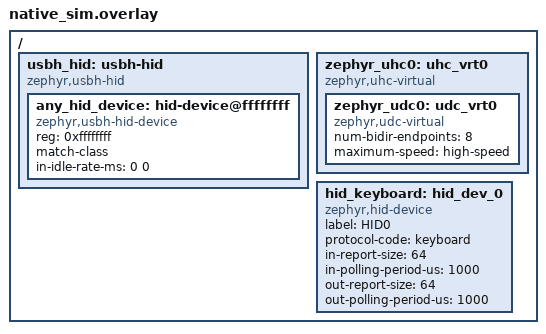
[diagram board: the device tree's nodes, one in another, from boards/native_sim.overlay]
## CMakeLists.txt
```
# SPDX-FileCopyrightText: Copyright 2026 Renesas, Embedd
# SPDX-License-Identifier: Apache-2.0

cmake_minimum_required(VERSION 3.20.0)

find_package(Zephyr REQUIRED HINTS $ENV{ZEPHYR_BASE})
project(test_usbh_hid)

include(${ZEPHYR_BASE}/samples/subsys/usb/common/common.cmake)

target_include_directories(app PRIVATE ${ZEPHYR_BASE}/tests/subsys/usb/host/common)
target_include_directories(app PRIVATE ${ZEPHYR_BASE}/subsys/usb/host)

target_sources(app PRIVATE src/keyboard.c src/hid_keyboard.c)
```

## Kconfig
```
# SPDX-FileCopyrightText: Copyright 2026 Renesas, Embedd
# SPDX-License-Identifier: Apache-2.0

config SYS_CLOCK_TICKS_PER_SEC
	default 1000000 if BOARD_NATIVE_SIM

# Source common USB sample options used to initialize new experimental USB
# device stack. The scope of these options is limited to USB samples in project
# tree, you cannot use them in your own application.
source "samples/subsys/usb/common/Kconfig.sample_usbd"

source "Kconfig.zephyr"
```

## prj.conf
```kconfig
# SPDX-FileCopyrightText: Copyright 2026 Renesas, Embedd
# SPDX-License-Identifier: Apache-2.0

CONFIG_LOG=y
CONFIG_ZTEST=y

CONFIG_USB_DEVICE_STACK_NEXT=y
CONFIG_SAMPLE_USBD_PID=0xFFFF
CONFIG_SAMPLE_USBD_REMOTE_WAKEUP=y
CONFIG_SAMPLE_USBD_PRODUCT="Zephyr USB HID Test"

CONFIG_UHC_DRIVER=y
CONFIG_USB_HOST_STACK=y

CONFIG_USBH_HID_CLASS=y
CONFIG_USBH_HID_ROUTE_TO_INPUT=y

CONFIG_INPUT=y
CONFIG_INPUT_MODE_SYNCHRONOUS=y
```

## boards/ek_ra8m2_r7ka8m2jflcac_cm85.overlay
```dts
/*
 * Copyright (c) 2026 Renesas Electronics Corporation
 *
 * SPDX-License-Identifier: Apache-2.0
 */

/ {
	usbh_hid: usbh-hid {
		compatible = "zephyr,usbh-hid";
		#address-cells = <1>;
		#size-cells = <0>;

		any_hid_device: hid-device@ffffffff {
			compatible = "zephyr,usbh-hid-device";
			reg = <0xffffffff>;
			match-class;
			in-idle-rate-ms = <0 0>;
		};
	};

	hid_keyboard: hid_dev_0 {
		compatible = "zephyr,hid-device";
		label = "HID0";
		protocol-code = "keyboard";
		in-report-size = <64>;
		in-polling-period-us = <1000>;
		out-report-size = <64>;
		out-polling-period-us = <1000>;
	};
};
```

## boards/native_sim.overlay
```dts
/*
 * SPDX-FileCopyrightText: Copyright 2026 Renesas, Embedd
 * SPDX-License-Identifier: Apache-2.0
 */

/delete-node/ &zephyr_udc0;

/ {
	usbh_hid: usbh-hid {
		compatible = "zephyr,usbh-hid";

		#address-cells = <1>;
		#size-cells = <0>;

		any_hid_device: hid-device@ffffffff {
		compatible = "zephyr,usbh-hid-device";
		reg = <0xffffffff>;
		match-class;
		in-idle-rate-ms = <0 0>;
		status="okay";
		};
	};
};

/ {
	zephyr_uhc0: uhc_vrt0 {
		compatible = "zephyr,uhc-virtual";

		zephyr_udc0: udc_vrt0 {
			compatible = "zephyr,udc-virtual";
			num-bidir-endpoints = <8>;
			maximum-speed = "high-speed";
		};
	};

	hid_keyboard: hid_dev_0 {
		compatible = "zephyr,hid-device";
		label = "HID0";
		protocol-code = "keyboard";
		in-report-size = <64>;
		in-polling-period-us = <1000>;
		out-report-size = <64>;
		out-polling-period-us = <1000>;
	};
};
```

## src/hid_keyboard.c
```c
/*
 * SPDX-FileCopyrightText: Copyright 2026 Renesas, Embedd
 * SPDX-License-Identifier: Apache-2.0
 */

#include <zephyr/ztest.h>
#include <zephyr/kernel.h>
#include <zephyr/device.h>
#include <zephyr/drivers/gpio.h>
#include <zephyr/input/input.h>
#include <zephyr/usb/usbd.h>
#include <zephyr/usb/class/usbd_hid.h>

#include "hid_keyboard.h"

static const uint8_t hid_report_desc[] = HID_KEYBOARD_REPORT_DESC();

static uint32_t kb_duration;
static uint8_t report_value;

static void kb_iface_ready(const struct device *dev, const bool ready)
{
}

static int kb_get_report(const struct device *dev, const uint8_t type, const uint8_t id,
			 const uint16_t len, uint8_t *const buf)
{
	return 0;
}

static int kb_set_report(const struct device *dev, const uint8_t type, const uint8_t id,
			 const uint16_t len, const uint8_t *const buf)
{
	if (type != HID_REPORT_TYPE_OUTPUT) {
		return -ENOTSUP;
	}

	return 0;
}

/* Idle duration is stored but not used to calculate idle reports. */
static void kb_set_idle(const struct device *dev, const uint8_t id, const uint32_t duration)
{
	kb_duration = duration;
}

static uint32_t kb_get_idle(const struct device *dev, const uint8_t id)
{
	return kb_duration;
}

static void kb_set_protocol(const struct device *dev, const uint8_t proto)
{
}

static void kb_output_report(const struct device *dev, const uint16_t len, const uint8_t *const buf)
{
	zassert_equal(1, len, "Wrong report length");
	kb_set_report(dev, HID_REPORT_TYPE_OUTPUT, 0u, len, buf);
	report_value = buf[0];
}

static struct hid_device_ops kb_ops = {
	.iface_ready = kb_iface_ready,
	.get_report = kb_get_report,
	.set_report = kb_set_report,
	.set_idle = kb_set_idle,
	.get_idle = kb_get_idle,
	.set_protocol = kb_set_protocol,
	.output_report = kb_output_report,
};

int hid_keyboard_register(void)
{
	const struct device *hid_dev = DEVICE_DT_GET(DT_NODELABEL(hid_keyboard));
	int result = 0;

	if (!device_is_ready(hid_dev)) {
		return -EIO;
	}

	result = hid_device_register(hid_dev, hid_report_desc, sizeof(hid_report_desc), &kb_ops);
	if (result != 0) {
		return result;
	}

	return 0;
}

uint8_t hid_keyboard_get_report_value(void)
{
	return report_value;
}
```

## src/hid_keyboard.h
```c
/*
 * SPDX-FileCopyrightText: Copyright 2026 Renesas, Embedd
 * SPDX-License-Identifier: Apache-2.0
 */

#ifndef HID_KEYBOARD_H_INCLUDED
#define HID_KEYBOARD_H_INCLUDED

#include <stdbool.h>
#include <stdint.h>

int hid_keyboard_register(void);
uint8_t hid_keyboard_get_report_value(void);

/**
 * @brief Configure the result the emulated keyboard's Get Report handler should give
 *
 * @param error 0 for a successful (dummy) report, a negative errno value to make the
 *              device reject (stall) the next Get Report requests
 */
void hid_keyboard_set_get_report_error(int error);

/**
 * @brief Configure whether the emulated keyboard advertises Set Idle support
 *
 * @param supported false to make the device reject (stall) Set Idle requests
 */
void hid_keyboard_set_idle_supported(bool supported);

#endif /* HID_KEYBOARD_H_INCLUDED */
```

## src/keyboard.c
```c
/*
 * SPDX-FileCopyrightText: Copyright 2026 Renesas, Embedd
 * SPDX-License-Identifier: Apache-2.0
 */

#include <zephyr/ztest.h>
#include <zephyr/usb/usbd.h>
#include <zephyr/usb/class/hid.h>
#include <zephyr/logging/log.h>
#include <zephyr/input/input.h>
#include <sample_usbd.h>
#include <zephyr/usb/class/usbd_hid.h>
#include <zephyr/usb/class/usbh_hid.h>

#include "usbh_desc.h"
#include "usbh_device.h"
#include "hid_keyboard.h"

LOG_MODULE_REGISTER(usbh_test_hid, LOG_LEVEL_INF);

#define MAX_EVENTS 16

struct usbh_hid_keyboard_suite_fixture {
	size_t expected_event_index;
	struct input_event expected_events[MAX_EVENTS];
	struct k_sem sync;
};

static struct device const *hid_dev = DEVICE_DT_GET(DT_NODELABEL(hid_keyboard));
static struct device const *usbh_hid_dev = DEVICE_DT_GET(DT_NODELABEL(any_hid_device));
static struct usbd_context *test_usbd;

USBH_CONTROLLER_DEFINE(test_uhs_ctx, DEVICE_DT_GET(DT_NODELABEL(zephyr_uhc0)));

struct usbh_context *const uhs_ctx = &test_uhs_ctx;

static struct usbh_hid_keyboard_suite_fixture fixture = {};

static void *suite_setup(void)
{
	int result = 0;

	k_sem_init(&fixture.sync, 0, 1);

	result = usbh_init(uhs_ctx);
	zassert_ok(result, "Failed to initialize USB host");

	result = usbh_enable(uhs_ctx);
	zassert_ok(result, "Failed to enable USB host");

	result = uhc_bus_reset(uhs_ctx->dev);
	zassert_ok(result, "Failed to signal bus reset");

	result = uhc_bus_resume(uhs_ctx->dev);
	zassert_ok(result, "Failed to signal bus resume");

	result = uhc_sof_enable(uhs_ctx->dev);
	zassert_ok(result, "Failed to enable SoF generator");

	result = hid_keyboard_register();
	zassert_ok(result, "Failed to register HID device");

	test_usbd = sample_usbd_setup_device(NULL);
	zassert_not_null(test_usbd, "Failed to setup USB device");

	result = usbd_init(test_usbd);
	zassert_ok(result, "Failed to initialize device support");

	result = usbd_enable(test_usbd);
	zassert_ok(result, "Failed to enable device support");

	/* Allow the host time to reset the device. */
	k_msleep(1000);

	result = usbh_hid_start_input_reports(usbh_hid_dev);
	zassert_ok(result, "Failed to start input reports");

	return NULL;
}

static void suite_shutdown(void *f)
{
	int result = 0;

	result = usbh_hid_stop_input_reports(usbh_hid_dev);
	zassert_ok(result, "Failed to stop HID input reports");

	result = usbd_disable(test_usbd);
	zassert_ok(result, "Failed to disable device support");

	result = usbd_shutdown(test_usbd);
	zassert_ok(result, "Failed to shutdown device support");

	LOG_INF("Device support disabled");

	result = usbh_disable(uhs_ctx);
	zassert_ok(result, "Failed to disable USB host");

	result = usbh_shutdown(uhs_ctx);
	zassert_ok(result, "Failed to shutdown host support");

	LOG_INF("Host controller disabled");
}

ZTEST_SUITE(usbh_hid_keyboard_suite, NULL, suite_setup, NULL, NULL, suite_shutdown);

ZTEST(usbh_hid_keyboard_suite, test_usbh_hid_keyboard_set_protocol)
{
	int result = 0;
	uint8_t protocol_code = 0;

	result = usbh_hid_set_protocol(usbh_hid_dev, HID_PROTOCOL_BOOT);
	zassert_ok(result, "Unable to set protocol");

	result = usbh_hid_get_protocol(usbh_hid_dev, &protocol_code);
	zassert_ok(result, "Unable to get protocol");
	zassert_equal(protocol_code, HID_PROTOCOL_BOOT, "Wrong protocol");

	result = usbh_hid_set_protocol(usbh_hid_dev, HID_PROTOCOL_REPORT);
	zassert_ok(result, "Unable to set protocol");

	result = usbh_hid_get_protocol(usbh_hid_dev, &protocol_code);
	zassert_ok(result, "Unable to get protocol");
	zassert_equal(protocol_code, HID_PROTOCOL_REPORT, "Wrong protocol");
}

ZTEST(usbh_hid_keyboard_suite, test_usbh_hid_keyboard_output_report)
{
	uint8_t const report[] = {0xF};
	int result = 0;

	result = usbh_hid_set_report(usbh_hid_dev, HID_REPORT_TYPE_OUTPUT, 0, sizeof(report),
				     report);
	zassert_ok(result, "Unable to set report");

	zassert_equal(report[0], hid_keyboard_get_report_value(), "Wrong report value");
}

ZTEST(usbh_hid_keyboard_suite, test_usbh_hid_keyboard_set_idle)
{
	int result = 0;
	uint16_t idle_period_ms = 0;

	/* Idle period must be a multiple of 4 */
	result = usbh_hid_set_idle_rate(usbh_hid_dev, 0, 501u);
	zassert_equal(result, -EINVAL, "Idle periods not divisible by 4 should be rejected");

	result = usbh_hid_set_idle_rate(usbh_hid_dev, 0, 255u * 4u + 1u);
	zassert_equal(result, -EINVAL,
		      "Idle periods beyond what fits in a byte should be rejected");

	result = usbh_hid_set_idle_rate(usbh_hid_dev, 0, 500u);
	zassert_ok(result, "Failed to set idle rate");

	result = usbh_hid_get_idle_rate(usbh_hid_dev, 0, &idle_period_ms);
	zassert_ok(result, "Failed to set idle rate");
	zassert_equal(idle_period_ms, 500u, "Wrong idle rate");

	result = usbh_hid_set_idle_rate(usbh_hid_dev, 0, 0u);
	zassert_ok(result, "Failed to set idle rate");

	result = usbh_hid_get_idle_rate(usbh_hid_dev, 0, &idle_period_ms);
	zassert_ok(result, "Failed to set idle rate");
	zassert_equal(idle_period_ms, 0u, "Wrong idle rate");
}

ZTEST(usbh_hid_keyboard_suite, test_usbh_hid_keyboard_input_single_keys)
{
	{
		/* X button press */
		uint8_t report[] = {0, 0, 0x1B, 0, 0, 0, 0, 0};

		memset(fixture.expected_events, 0, sizeof(fixture.expected_events));
		fixture.expected_event_index = 0;
		fixture.expected_events[0].type = INPUT_EV_KEY;
		fixture.expected_events[0].code = INPUT_KEY_X;
		fixture.expected_events[0].value = 1;

		hid_device_submit_report(hid_dev, sizeof(report), report);
		k_sem_take(&fixture.sync, K_FOREVER);
	}

	{
		/* X button release */
		uint8_t report[] = {0, 0, 0, 0, 0, 0, 0, 0};

		memset(fixture.expected_events, 0, sizeof(fixture.expected_events));
		fixture.expected_event_index = 0;
		fixture.expected_events[0].type = INPUT_EV_KEY;
		fixture.expected_events[0].code = INPUT_KEY_X;
		fixture.expected_events[0].value = 0;

		hid_device_submit_report(hid_dev, sizeof(report), report);
		k_sem_take(&fixture.sync, K_FOREVER);
	}

	{
		/* Left control modifier press */
		uint8_t report[] = {1, 0, 0, 0, 0, 0, 0, 0};

		memset(fixture.expected_events, 0, sizeof(fixture.expected_events));
		fixture.expected_event_index = 0;
		fixture.expected_events[0].type = INPUT_EV_KEY;
		fixture.expected_events[0].code = INPUT_KEY_LEFTCTRL;
		fixture.expected_events[0].value = 1;

		hid_device_submit_report(hid_dev, sizeof(report), report);
		k_sem_take(&fixture.sync, K_FOREVER);
	}

	{
		/* Left control modifier release */
		uint8_t report[] = {0, 0, 0, 0, 0, 0, 0, 0};

		memset(fixture.expected_events, 0, sizeof(fixture.expected_events));
		fixture.expected_event_index = 0;
		fixture.expected_events[0].type = INPUT_EV_KEY;
		fixture.expected_events[0].code = INPUT_KEY_LEFTCTRL;
		fixture.expected_events[0].value = 0;

		hid_device_submit_report(hid_dev, sizeof(report), report);
		k_sem_take(&fixture.sync, K_FOREVER);
	}
}

ZTEST(usbh_hid_keyboard_suite, test_usbh_hid_keyboard_input_multiple_keys)
{
	{
		/* Left control, X and Y press */
		uint8_t report[] = {1, 0, 0x1B, 0x1C, 0, 0, 0, 0};

		memset(fixture.expected_events, 0, sizeof(fixture.expected_events));
		fixture.expected_event_index = 0;
		fixture.expected_events[0].type = INPUT_EV_KEY;
		fixture.expected_events[0].code = INPUT_KEY_LEFTCTRL;
		fixture.expected_events[0].value = 1;

		fixture.expected_events[1].type = INPUT_EV_KEY;
		fixture.expected_events[1].code = INPUT_KEY_X;
		fixture.expected_events[1].value = 1;

		fixture.expected_events[2].type = INPUT_EV_KEY;
		fixture.expected_events[2].code = INPUT_KEY_Y;
		fixture.expected_events[2].value = 1;

		hid_device_submit_report(hid_dev, sizeof(report), report);
		k_sem_take(&fixture.sync, K_FOREVER);
	}

	{
		/* X release */
		uint8_t report[] = {1, 0, 0x1C, 0, 0, 0, 0, 0};

		memset(fixture.expected_events, 0, sizeof(fixture.expected_events));
		fixture.expected_event_index = 0;
		fixture.expected_events[0].type = INPUT_EV_KEY;
		fixture.expected_events[0].code = INPUT_KEY_LEFTCTRL;
		fixture.expected_events[0].value = 1;

		fixture.expected_events[1].type = INPUT_EV_KEY;
		fixture.expected_events[1].code = INPUT_KEY_Y;
		fixture.expected_events[1].value = 1;

		fixture.expected_events[2].type = INPUT_EV_KEY;
		fixture.expected_events[2].code = INPUT_KEY_X;
		fixture.expected_events[2].value = 0;

		hid_device_submit_report(hid_dev, sizeof(report), report);
		k_sem_take(&fixture.sync, K_FOREVER);
	}

	{
		/* Left control and Y release */
		uint8_t report[] = {0, 0, 0, 0, 0, 0, 0, 0};

		memset(fixture.expected_events, 0, sizeof(fixture.expected_events));
		fixture.expected_event_index = 0;
		fixture.expected_events[0].type = INPUT_EV_KEY;
		fixture.expected_events[0].code = INPUT_KEY_LEFTCTRL;
		fixture.expected_events[0].value = 0;

		fixture.expected_events[1].type = INPUT_EV_KEY;
		fixture.expected_events[1].code = INPUT_KEY_Y;
		fixture.expected_events[1].value = 0;

		hid_device_submit_report(hid_dev, sizeof(report), report);
		k_sem_take(&fixture.sync, K_FOREVER);
	}
}

static void verify_input_cb(struct input_event *evt, void *user_data)
{
	zassert_equal(fixture.expected_events[fixture.expected_event_index].type, evt->type,
		      "Wrong input event type");
	zassert_equal(fixture.expected_events[fixture.expected_event_index].code, evt->code,
		      "Wrong input event code");
	zassert_equal(fixture.expected_events[fixture.expected_event_index].value, evt->value,
		      "Wrong input event value");

	fixture.expected_event_index++;

	if (fixture.expected_events[fixture.expected_event_index].type == 0u) {
		k_sem_give(&fixture.sync);
	}
}

INPUT_CALLBACK_DEFINE(NULL, verify_input_cb, NULL);
```
